# Generic_ARMv8MBaseline register map
Vendor: ARM Ltd.; Series: ARMv8-M Baseline architecture (Cortex-M23); File version: 1.0
CPU: CM23 r0p0, little endian, no MPU, no FPU, 2 interrupt priority bits
Registers are 32-bit, read-write, reset 0x0 unless marked. A register's access mark holds for its fields unless they carry their own. Offsets are from the block's base; [hi:lo] are bit positions; {n}, {i} and the like mark numbered series.

## NVIC — Nested Vectored Interrupt Controller. ARMv8-M packs interrupt state into 16 banks of 32 bits each (ISER/ICER/ISPR/ICPR/IABR/ITNS) plus 124 32-bit IPR words, covering the full architectural maximum of 496 external interrupts (verified against CMSIS_6 core_cm23.h/core_cm33.h: IPR is a 496-byte array, i.e. 124 words of 4 packed 8-bit priorities each -- same total on both profiles). ITNS (Interrupt Target Non-Secure) is new versus ARMv6-M/ARMv7-M: one bit per interrupt selecting whether it targets the Secure or the Non-secure state; Secure-only access, and RAZ/WI when the Security Extension is not implemented. No STIR on Baseline, matching ARMv6-M (STIR is Mainline-only across the whole Cortex-M family).
Base 0xE000E100
{0x0+4i} ISER{i} (i=0..15) — Interrupt Set-Enable Register
  [31:0] BITS
{0x80+4i} ICER{i} (i=0..15) — Interrupt Clear-Enable Register
  [31:0] BITS
{0x100+4i} ISPR{i} (i=0..15) — Interrupt Set-Pending Register
  [31:0] BITS
{0x180+4i} ICPR{i} (i=0..15) — Interrupt Clear-Pending Register
  [31:0] BITS
{0x200+4i} IABR{i} (i=0..15) ro — Interrupt Active Bit Register
  [31:0] BITS
{0x280+4i} ITNS{i} (i=0..15) — Interrupt Target Non-Secure Register -- Security Extension only, Secure-accessible
  [31:0] BITS
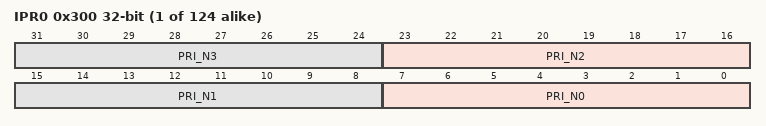
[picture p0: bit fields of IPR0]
{0x300+4i} IPR{i} (i=0..123) — Interrupt Priority Registers 0-123 (cover IRQ0..IRQ495)
  [8n+7:8n] PRI_N{n} (n=0..3) — Priority, byte offset {n}

## SCB — System Control Block, ARMv8-M Baseline register set. Verified against CMSIS_6 core_cm23.h. Minimal fault model like ARMv6-M -- no SHPR1, no CFSR/HFSR/MMFAR/BFAR/AFSR/CPACR/NSACR/SFSR/SFAR/ID_* registers at all (no MemManage/BusFault/UsageFault/SecureFault handlers on Baseline), no AIRCR.PRIGROUP (fixed priority split, like ARMv6-M). Unlike ARMv6-M, ICSR.RETTOBASE exists and SHCSR is normally accessible from application code, not DAP-only. Gains the Security Extension fields (ICSR.STTNS, AIRCR.SYSRESETREQS/BFHFNMINS/PRIS, SCR.SLEEPDEEPS, SHCSR.HARDFAULT*/NMIACT) -- Secure-only/RAZ-WI when the Security Extension is not implemented. CCR.STKALIGN and CCR.NONBASETHRDENA no longer exist as configurable bits, see the CCR register below.
Base 0xE000ED00
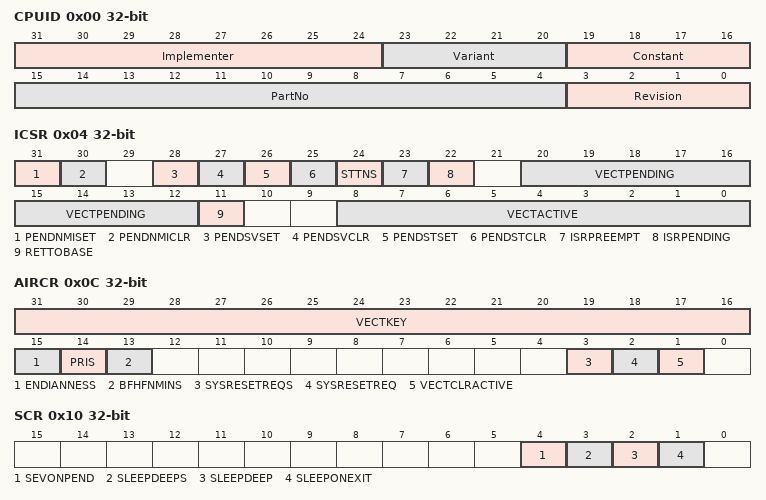
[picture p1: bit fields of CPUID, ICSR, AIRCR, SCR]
0x00 CPUID ro — CPUID Base Register. Reset value is implementation/revision specific.
  [31:24] Implementer — 0x41 = 'A' = ARM
  [23:20] Variant — Implementation specific variant number
  [19:16] Constant — Reads as 0xC for ARMv6-M, 0xF for ARMv7-M/ARMv8-M
  [15:4] PartNo — Implementation specific part number
  [3:0] Revision — Implementation/revision specific (e.g. r0p0 = 0x0)
0x04 ICSR — Interrupt Control and State Register
  [31] PENDNMISET — aka NMIPENDSET
  [30] PENDNMICLR wo — New in ARMv8-M
  [28] PENDSVSET
  [27] PENDSVCLR wo
  [26] PENDSTSET
  [25] PENDSTCLR wo
  [24] STTNS — Secure Transition To Non-secure -- Security Extension only, banked, RAZ/WI from Non-secure state
  [23] ISRPREEMPT ro
  [22] ISRPENDING ro
  [20:12] VECTPENDING
  [11] RETTOBASE ro
  [8:0] VECTACTIVE
0x08 VTOR — Vector Table Offset Register -- OPTIONAL: implementation-defined whether present (__VTOR_PRESENT); reads as 0 / reserved when absent.
  [31:7] TBLOFF
0x0C AIRCR — Application Interrupt and Reset Control Register. No PRIGROUP (fixed priority grouping, like ARMv6-M).
  [31:16] VECTKEY — Write 0x05FA to permit the write; reads as 0xFA05
  [15] ENDIANNESS ro — Renamed from ENDIANESS in CMSIS_6 (kept as a deprecated alias there)
  [14] PRIS — Prioritize Secure exceptions -- Security Extension only
  [13] BFHFNMINS — BusFault/HardFault/NMI target Non-secure state when set -- Security Extension only
  [3] SYSRESETREQS — SYSRESETREQ traps to Secure state when set -- Security Extension only
  [2] SYSRESETREQ
  [1] VECTCLRACTIVE — Reserved for debug use
0x10 SCR — System Control Register
  [4] SEVONPEND
  [3] SLEEPDEEPS — SLEEPDEEP usable from Non-secure state -- Security Extension only
  [2] SLEEPDEEP
  [1] SLEEPONEXIT
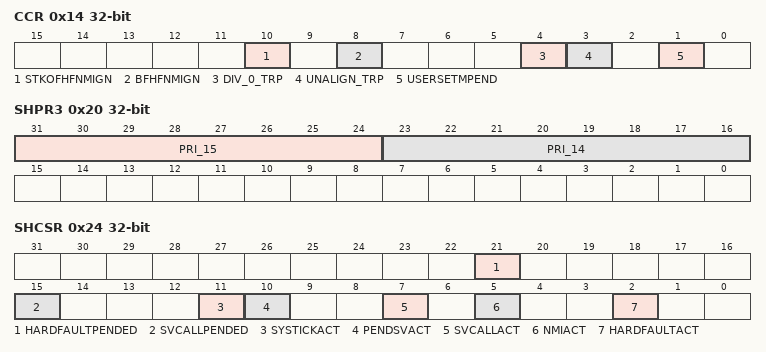
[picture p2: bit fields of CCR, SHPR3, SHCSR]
0x14 CCR — Configuration and Control Register
  [10] STKOFHFNMIGN — Ignore stack overflow while handling a HardFault/NMI/FAULTMASK-escalated fault -- new in ARMv8-M
  [8] BFHFNMIGN
  [4] DIV_0_TRP
  [3] UNALIGN_TRP
  [1] USERSETMPEND
0x1C SHPR2 — System Handler Priority Register 2
  [31:24] PRI_11 — Priority of exception 11, SVCall
0x20 SHPR3 — System Handler Priority Register 3
  [31:24] PRI_15 — Priority of exception 15, SysTick
  [23:16] PRI_14 — Priority of exception 14, PendSV
0x24 SHCSR — System Handler Control and State Register
  [21] HARDFAULTPENDED — New in ARMv8-M
  [15] SVCALLPENDED
  [11] SYSTICKACT
  [10] PENDSVACT
  [7] SVCALLACT
  [5] NMIACT — New in ARMv8-M: HardFault/NMI gets a trackable active bit
  [2] HARDFAULTACT
